# S6E2HGxE register map
Vendor: Spansion; File version: 2.0
CPU: CM4 r0p1, little endian, MPU, FPU, 4 interrupt priority bits
Registers are 32-bit, read-write, reset 0x0 unless marked. A register's access mark holds for its fields unless they carry their own. Offsets are from the block's base; [hi:lo] are bit positions; {n}, {i} and the like mark numbered series; 'fields as' and 'values as' point back to an identical list.

## DAC0 — D/A Converter 0
Base 0x40033000
Same registers: DAC1 0x40033008
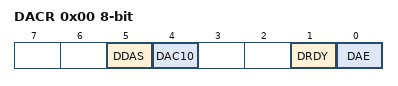
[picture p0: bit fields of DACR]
0x00 DACR 8-bit — D/A Control Register
  [5] DDAS — 10-bit mode data allocation selection bit
  [4] DAC10 — 10-bit mode
  [1] DRDY ro — D/A converter operation enable state bit
  [0] DAE — D/A converter operating enable bit
0x04 DADR 16-bit reset not defined — D/A Data Register
  [11:0] DA

## LVD — Low-voltage Detection
Base 0x40035000
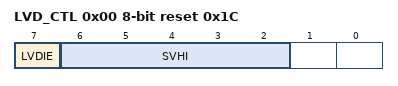
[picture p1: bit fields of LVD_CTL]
0x00 LVD_CTL 8-bit reset 0x1C — Low-voltage Detection Voltage Control Register
  [7] LVDIE — Low-voltage detection interrupt enable bit
  [6:2] SVHI — Low-voltage detection interrupt voltage setting bits
0x04 LVD_STR 8-bit ro — Low-voltage Detection Interrupt Factor Register
  [7] LVDIR — Low-voltage detection interrupt factor bit
0x08 LVD_CLR 8-bit reset 0x80 — Low-voltage Detection Interrupt Factor Clear Register
  [7] LVDCL — Low-voltage detection interrupt factor clear bit
0x0C LVD_RLR reset 0x1 — Low-voltage Detection Voltage Protection Register
  [31:0] LVDLCK — Low-voltage Detection Voltage Control Register protection bits
0x10 LVD_STR2 8-bit ro — Low-voltage Detection Circuit Status Register
  [7] LVDIRDY — Low-voltage detection interrupt status flag

## DS — Low Power Consumption Mode
Base 0x40035100
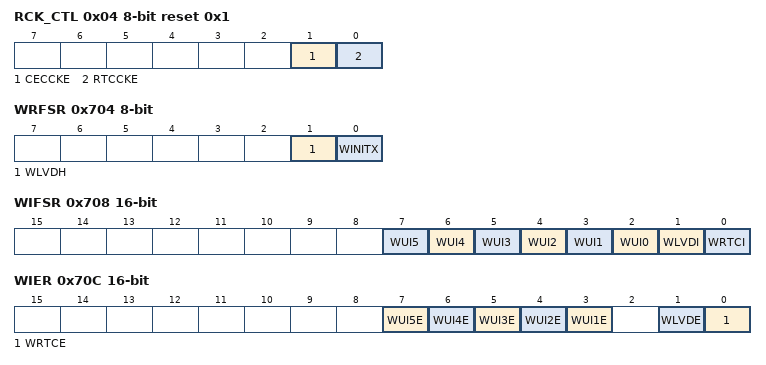
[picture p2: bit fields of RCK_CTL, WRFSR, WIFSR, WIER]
0x04 RCK_CTL 8-bit reset 0x1 — Sub Clock Control Register
  [1] CECCKE — CEC clock control bit
  [0] RTCCKE — RTC clock control bit
0x700 PMD_CTL 8-bit — RTC Mode Control Register
  [0] RTCE — RTC mode control bit
0x704 WRFSR 8-bit ro — Deep Standby Return Cause Register 1
  [1] WLVDH — Low-voltage detection reset return bit
  [0] WINITX — INITX pin input reset return bit
0x708 WIFSR 16-bit ro — Deep Standby Return Cause Register 2
  [n+2] WUI{n} (n=0..5) — WKUP pin input return bit {n}
  [1] WLVDI — LVD interrupt return bit
  [0] WRTCI — RTC interrupt return bit
0x70C WIER 16-bit — Deep Standby Return Enable Register
  [n+2] WUI{n}E (n=1..5) — WKUP pin input return enable bit {n}
  [1] WLVDE — LVD interrupt return enable bit
  [0] WRTCE — RTC interrupt return enable bit
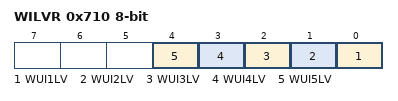
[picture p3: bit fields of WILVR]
0x710 WILVR 8-bit — WKUP Pin Input Level Register
  [n-1] WUI{n}LV (n=1..5) — WKUP pin input level select bit {n}
0x714 DSRAMR 8-bit — Deep Standby RAM Retention Register
  [1:0] SRAMR — On-chip SRAM retention control bits
{0x7FF+i} BUR{i:02} 8-bit (i=1..16) — Backup Registers from {i}

## CANPRES — CAN Prescaler Register
Base 0x40037000
0x00 CANPRE 8-bit reset 0xB — CAN Prescaler Register
  [3:0] CANPRE — CAN prescaler setting bits

## CRC — CRC Registers
Base 0x40039000
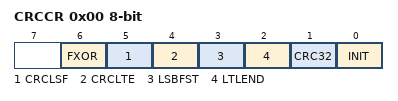
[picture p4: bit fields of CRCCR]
0x00 CRCCR 8-bit — CRC Control Register
  [6] FXOR — Initialization bit
  [5] CRCLSF — Final XOR control bit
  [4] CRCLTE — CRC result bit-order setting bit
  [3] LSBFST — CRC result byte-order setting bit
  [2] LTLEND — Bit-order setting bit
  [1] CRC32 — Byte-order setting bit
  [0] INIT — CRC mode selection bit
0x04 CRCINIT reset 0xFFFFFFFF — Initial Value Register
  [31:0] D — Initial value
0x08 CRCIN — Input Data Register
  [31:0] D — Input data
0x0C CRCR ro reset 0xFFFFFFFF — CRC Register
  [31:0] D — CRC Data

## WC — Watch Counter
Base 0x4003A000
0x00 WCRD 8-bit ro — Watch Counter Read Register
  [5:0] CTR — Counter read bits
0x01 WCRL 8-bit — Watch Counter Reload Register
  [5:0] RLC — Counter reload value setting bits
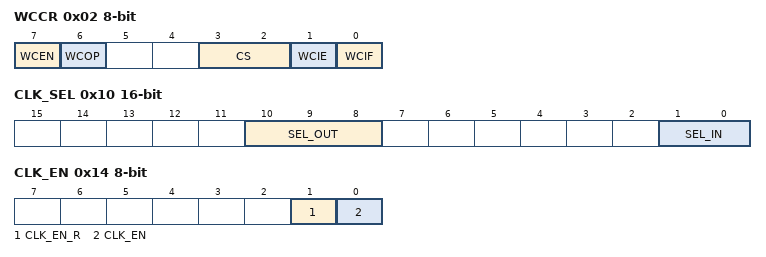
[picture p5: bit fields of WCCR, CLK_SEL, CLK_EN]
0x02 WCCR 8-bit — Watch Counter Control Register
  [7] WCEN — Watch counter operation enable bit
  [6] WCOP ro — Watch counter operating state flag
  [3:2] CS — Count clock select bits
  [1] WCIE — Interrupt request enable bit
  [0] WCIF — Interrupt request flag bit
0x10 CLK_SEL 16-bit — Clock Selection Register
  [10:8] SEL_OUT — Output clock selection bit
  [1:0] SEL_IN — Input clock selection bit
0x14 CLK_EN 8-bit — Division Clock Enable Register
  [1] CLK_EN_R — Division clock enable read bit
  [0] CLK_EN — Division clock enable bit

## LSCRP — Low-speed CR Prescaler
Base 0x4003C000
0x00 LCR_PRSLD 8-bit — Low-speed CR Prescaler Control Register
  [5:0] LCR_PRSLD — Low-speed CR Prescaler Load

## DMAC — DMAC Registers
Base 0x40060000
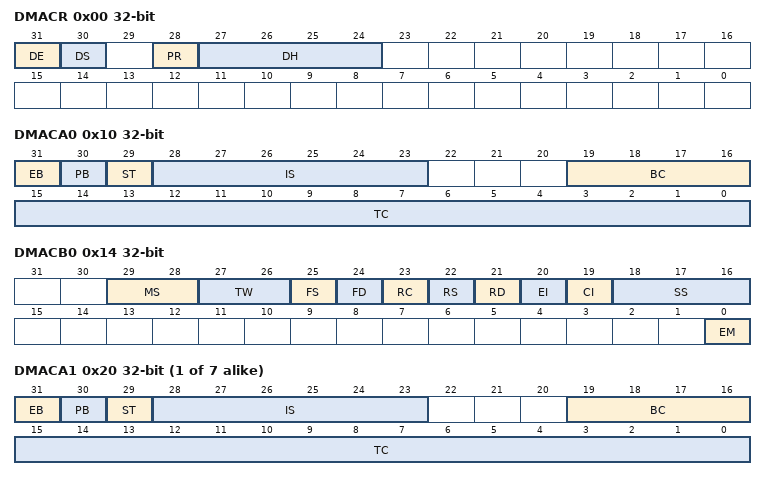
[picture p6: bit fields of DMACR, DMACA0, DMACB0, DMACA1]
0x00 DMACR — Entire DMAC Configuration Register
  [31] DE — DMA Enable (all-channel operation enable bit)
  [30] DS — DMA Stop
  [28] PR — Priority Rotation
  [27:24] DH — DMA Halt (All-channel pause bit)
0x10 DMACA0 — Configuration A Register
  [31] EB — Enable bit (individual-channel operation enable bit)
  [30] PB — Pause bit (individual-channel pause bit)
  [29] ST — Software Trigger
  [28:23] IS — Input Select
  [19:16] BC — Block Count
  [15:0] TC — Transfer Count
0x14 DMACB0 — Configuration B Register
  [29:28] MS — Mode Select
  [27:26] TW — Transfer Width
  [25] FS — Fixed Source
  [24] FD — Fixed Destination
  [23] RC — Reload Count (BC/TC reload)
  [22] RS — Reload Source
  [21] RD — Reload Destination
  [20] EI — Error Interrupt (unsuccessful transfer completion interrupt enable)
  [19] CI — Completion Interrupt (successful transfer completion interrupt enable)
  [18:16] SS — Stop Status (stop status notification)
  [0] EM — Enable bit Mask (EB bit clear mask)
0x18 DMACSA0 — Transfer Source Address Register
0x1C DMACDA0 — Transfer Destination Address Register
{0x10+0x10*i} DMACA{i} (i=1..7) — Configuration A Register {i}
  fields as DMACA0
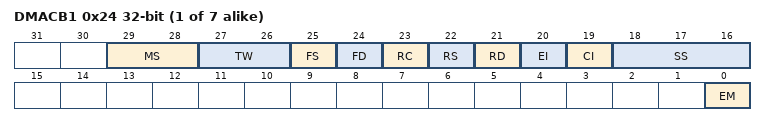
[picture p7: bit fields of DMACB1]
{0x14+0x10*i} DMACB{i} (i=1..7) — Configuration B Register {i}
  fields as DMACB0
{0x18+0x10*i} DMACSA{i} (i=1..7) — Transfer Source Address Register {i}
{0x1C+0x10*i} DMACDA{i} (i=1..7) — Transfer Destination Address Register {i}

## DSTC — DSTC registers
Base 0x40061000
0x00 DESTP — Descriptor top address Register
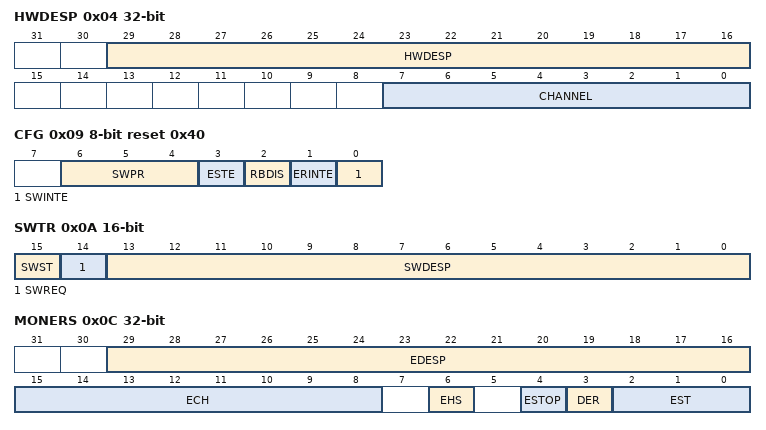
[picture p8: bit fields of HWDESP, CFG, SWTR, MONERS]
0x04 HWDESP — Hardware DES pointer Register
  [29:16] HWDESP, [7:0] CHANNEL
0x08 CMD 8-bit reset 0x1 — Command Register
0x09 CFG 8-bit reset 0x40 — Configuration Register
  [6:4] SWPR — Software transfer priority
  [3] ESTE — Error stop enable
  [2] RBDIS — Read skip buffer disable
  [1] ERINTE — Error interrupt enable
  [0] SWINTE — Software interrupt enable
0x0A SWTR 16-bit — Software trigger Register
  [15] SWST ro — Software status
  [14] SWREQ ro — Software request
  [13:0] SWDESP — Software DES pointer
0x0C MONERS ro — Transfer Error Status Monitor Register
  [29:16] EDESP — Error DES pointer
  [15:8] ECH — Error hardware channel
  [6] EHS — Error hardware software
  [4] ESTOP — Error stop
  [3] DER — Double error
  [2:0] EST — Error status
{0x10+4i} DREQENB{i} (i=0..7) — DMA request enable Register {i}
{0x30+4i} HWINT{i} ro (i=0..7) — Hardware transfer interrupt Register {i}
{0x50+4i} HWINTCLR{i} wo (i=0..7) — Hardware transfer interrupt clear Register {i}
{0x70+4i} DQMSK{i} ro (i=0..7) — DMA request mask Register {i}
{0x90+4i} DQMSKCLR{i} wo (i=0..7) — DMA request mask clear Register {i}

## WORKFLASH_IF — WorkFlash Memory
Base 0x200E0000
0x00 WFASZR reset 0x1 — WorkFlash Access Size Register
  [0] ASZ — WorkFlash Access Size
0x04 WFRWTR reset 0x4 — WorkFlash Read Wait Register
  [2:0] RWT — Read Wait Cycle
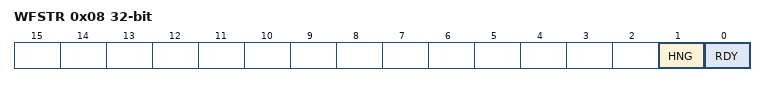
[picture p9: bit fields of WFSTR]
0x08 WFSTR ro — WorkFlash Status Register
  [1] HNG — WorkFlash Hang
  [0] RDY — WorkFlash Rdy
